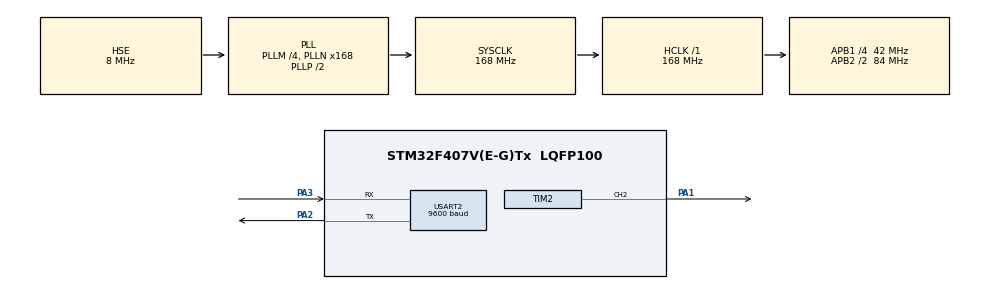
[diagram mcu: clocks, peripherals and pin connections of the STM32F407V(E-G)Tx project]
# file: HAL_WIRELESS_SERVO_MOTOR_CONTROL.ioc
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Mcu.Family=STM32F4
Mcu.Name=STM32F407V(E-G)Tx
Mcu.Package=LQFP100
NVIC.PriorityGroup=NVIC_PRIORITYGROUP_4
PA1.Signal=S_TIM2_CH2
PA2.Mode=Asynchronous
PA2.Signal=USART2_TX
PA3.Mode=Asynchronous
PA3.Signal=USART2_RX
PH0-OSC_IN.Mode=HSE-External-Oscillator
PH0-OSC_IN.Signal=RCC_OSC_IN
PH1-OSC_OUT.Mode=HSE-External-Oscillator
PH1-OSC_OUT.Signal=RCC_OSC_OUT
ProjectManager.HeapSize=0x200
ProjectManager.StackSize=0x400
ProjectManager.TargetToolchain=STM32CubeIDE
RCC.48MHZClocksFreq_Value=84000000
RCC.AHBFreq_Value=168000000
RCC.APB1CLKDivider=RCC_HCLK_DIV4
RCC.APB1Freq_Value=42000000
RCC.APB1TimFreq_Value=84000000
RCC.APB2CLKDivider=RCC_HCLK_DIV2
RCC.APB2Freq_Value=84000000
RCC.APB2TimFreq_Value=168000000
RCC.CortexFreq_Value=168000000
RCC.HCLKFreq_Value=168000000
RCC.HSE_VALUE=8000000
RCC.HSI_VALUE=16000000
RCC.LSE_VALUE=32768
RCC.PLLM=4
RCC.PLLN=168
RCC.PLLSourceVirtual=RCC_PLLSOURCE_HSE
RCC.SYSCLKFreq_VALUE=168000000
RCC.SYSCLKSource=RCC_SYSCLKSOURCE_PLLCLK
RCC.VCOOutputFreq_Value=336000000
SH.S_TIM2_CH2.0=TIM2_CH2,PWM Generation2 CH2
TIM2.Channel-PWM\ Generation2\ CH2=TIM_CHANNEL_2
TIM2.Period=19999
TIM2.Prescaler=83
USART2.BaudRate=9600
USART2.VirtualMode=VM_ASYNC
board=custom

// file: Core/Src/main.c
/* USER CODE BEGIN Header */
/**
  ******************************************************************************
  * @file           : main.c
  * @brief          : Main program body
  ******************************************************************************
  * @attention
  *
  * Copyright (c) 2024 STMicroelectronics.
  * All rights reserved.
  *
  * This software is licensed under terms that can be found in the LICENSE file
  * in the root directory of this software component.
  * If no LICENSE file comes with this software, it is provided AS-IS.
  *
  ******************************************************************************
  */
/* USER CODE END Header */
#include "main.h"

/* USER CODE BEGIN Includes */
#include <stdio.h>
#include <string.h>
/* USER CODE END Includes */

TIM_HandleTypeDef htim2;

UART_HandleTypeDef huart2;

void SystemClock_Config(void);
static void MX_GPIO_Init(void);
static void MX_TIM2_Init(void);
static void MX_USART2_UART_Init(void);

/* USER CODE BEGIN 0 */
uint16_t pulse;
uint8_t angle;
char tx_buffer[50], rx_buffer[50]={0}, char1, char2, char3;

/**
 * @brief Map a value from one range to another
 * @param in_value Input value to be mapped
 * @param in_min Minimum value of the input range
 * @param in_max Maximum value of the input range
 * @param out_min Minimum value of the output range
 * @param out_max Maximum value of the output range
 * @retval Mapped value
 */
uint16_t map_value(uint8_t in_value, uint8_t in_min, uint8_t in_max, uint16_t out_min, uint16_t out_max)
{
    return out_min + ((in_value - in_min) * (out_max - out_min)) / (in_max - in_min);
}

/**
 * @brief Configure UART to receive data and control servo motor based on received angle
 */
void uart_config()
{
	HAL_UART_Receive(&huart2, (uint8_t*)rx_buffer, 50, 100);
	if(rx_buffer[0]=='a' && rx_buffer[1]=='n' && rx_buffer[2]=='g' && rx_buffer[3]=='l' &&
			rx_buffer[4]=='e' && rx_buffer[5]==' ')
	{
		if(rx_buffer[8]=='\0' && rx_buffer[7]!='\0' && rx_buffer[6]!='\0')
		{
			angle = (rx_buffer[6]-'0')*10+(rx_buffer[7]-'0');
		}
		else if(rx_buffer[8]!='\0' && rx_buffer[7]!='\0' && rx_buffer[6]!='\0')
		{
			angle = (rx_buffer[6]-'0')*100+(rx_buffer[7]-'0')*10+(rx_buffer[8]-'0');
		}
		else
		{
			angle = (rx_buffer[6]-'0');
		}
		memset(rx_buffer, '\0', 50);

		pulse=map_value(angle,0,180,499,2499);
		__HAL_TIM_SET_COMPARE(&htim2, TIM_CHANNEL_2, pulse);

		HAL_UART_Transmit(&huart2, (uint8_t*)tx_buffer, sprintf(tx_buffer,"The angle is %u\n",angle), 100);
	}
}
/* USER CODE END 0 */

int main(void)
{

  /* MCU Configuration--------------------------------------------------------*/

  /* Reset of all peripherals, Initializes the Flash interface and the Systick. */
  HAL_Init();

  /* Configure the system clock */
  SystemClock_Config();

  /* Initialize all configured peripherals */
  MX_GPIO_Init();
  MX_TIM2_Init();
  MX_USART2_UART_Init();
  /* USER CODE BEGIN 2 */
  HAL_TIM_PWM_Start(&htim2, TIM_CHANNEL_2);
  memset(rx_buffer, '\0', 50);
  HAL_UART_Transmit(&huart2, (uint8_t*)(tx_buffer), sprintf(tx_buffer,"Please Enter The Angle\n"), 100);

  /* USER CODE END 2 */

  /* Infinite loop */
  while (1)
  {

    /* USER CODE BEGIN 3 */
	  uart_config();

  }
  /* USER CODE END 3 */
}

void SystemClock_Config(void)
{
  RCC_OscInitTypeDef RCC_OscInitStruct = {0};
  RCC_ClkInitTypeDef RCC_ClkInitStruct = {0};

  /** Configure the main internal regulator output voltage
  */
  __HAL_RCC_PWR_CLK_ENABLE();
  __HAL_PWR_VOLTAGESCALING_CONFIG(PWR_REGULATOR_VOLTAGE_SCALE1);

  /** Initializes the RCC Oscillators according to the specified parameters
  * in the RCC_OscInitTypeDef structure.
  */
  RCC_OscInitStruct.OscillatorType = RCC_OSCILLATORTYPE_HSE;
  RCC_OscInitStruct.HSEState = RCC_HSE_ON;
  RCC_OscInitStruct.PLL.PLLState = RCC_PLL_ON;
  RCC_OscInitStruct.PLL.PLLSource = RCC_PLLSOURCE_HSE;
  RCC_OscInitStruct.PLL.PLLM = 4;
  RCC_OscInitStruct.PLL.PLLN = 168;
  RCC_OscInitStruct.PLL.PLLP = RCC_PLLP_DIV2;
  RCC_OscInitStruct.PLL.PLLQ = 4;
  if (HAL_RCC_OscConfig(&RCC_OscInitStruct) != HAL_OK)
  {
    Error_Handler();
  }

  /** Initializes the CPU, AHB and APB buses clocks
  */
  RCC_ClkInitStruct.ClockType = RCC_CLOCKTYPE_HCLK|RCC_CLOCKTYPE_SYSCLK
                              |RCC_CLOCKTYPE_PCLK1|RCC_CLOCKTYPE_PCLK2;
  RCC_ClkInitStruct.SYSCLKSource = RCC_SYSCLKSOURCE_PLLCLK;
  RCC_ClkInitStruct.AHBCLKDivider = RCC_SYSCLK_DIV1;
  RCC_ClkInitStruct.APB1CLKDivider = RCC_HCLK_DIV4;
  RCC_ClkInitStruct.APB2CLKDivider = RCC_HCLK_DIV2;

  if (HAL_RCC_ClockConfig(&RCC_ClkInitStruct, FLASH_LATENCY_5) != HAL_OK)
  {
    Error_Handler();
  }
}

static void MX_TIM2_Init(void)
{

  TIM_MasterConfigTypeDef sMasterConfig = {0};
  TIM_OC_InitTypeDef sConfigOC = {0};

  htim2.Instance = TIM2;
  htim2.Init.Prescaler = 83;
  htim2.Init.CounterMode = TIM_COUNTERMODE_UP;
  htim2.Init.Period = 19999;
  htim2.Init.ClockDivision = TIM_CLOCKDIVISION_DIV1;
  htim2.Init.AutoReloadPreload = TIM_AUTORELOAD_PRELOAD_DISABLE;
  if (HAL_TIM_PWM_Init(&htim2) != HAL_OK)
  {
    Error_Handler();
  }
  sMasterConfig.MasterOutputTrigger = TIM_TRGO_RESET;
  sMasterConfig.MasterSlaveMode = TIM_MASTERSLAVEMODE_DISABLE;
  if (HAL_TIMEx_MasterConfigSynchronization(&htim2, &sMasterConfig) != HAL_OK)
  {
    Error_Handler();
  }
  sConfigOC.OCMode = TIM_OCMODE_PWM1;
  sConfigOC.Pulse = 0;
  sConfigOC.OCPolarity = TIM_OCPOLARITY_HIGH;
  sConfigOC.OCFastMode = TIM_OCFAST_DISABLE;
  if (HAL_TIM_PWM_ConfigChannel(&htim2, &sConfigOC, TIM_CHANNEL_2) != HAL_OK)
  {
    Error_Handler();
  }
  HAL_TIM_MspPostInit(&htim2);

}

static void MX_USART2_UART_Init(void)
{

  huart2.Instance = USART2;
  huart2.Init.BaudRate = 9600;
  huart2.Init.WordLength = UART_WORDLENGTH_8B;
  huart2.Init.StopBits = UART_STOPBITS_1;
  huart2.Init.Parity = UART_PARITY_NONE;
  huart2.Init.Mode = UART_MODE_TX_RX;
  huart2.Init.HwFlowCtl = UART_HWCONTROL_NONE;
  huart2.Init.OverSampling = UART_OVERSAMPLING_16;
  if (HAL_UART_Init(&huart2) != HAL_OK)
  {
    Error_Handler();
  }

}

static void MX_GPIO_Init(void)
{

  /* GPIO Ports Clock Enable */
  __HAL_RCC_GPIOH_CLK_ENABLE();
  __HAL_RCC_GPIOA_CLK_ENABLE();

}

void Error_Handler(void)
{
  __disable_irq();
  while (1)
  {
  }
}
